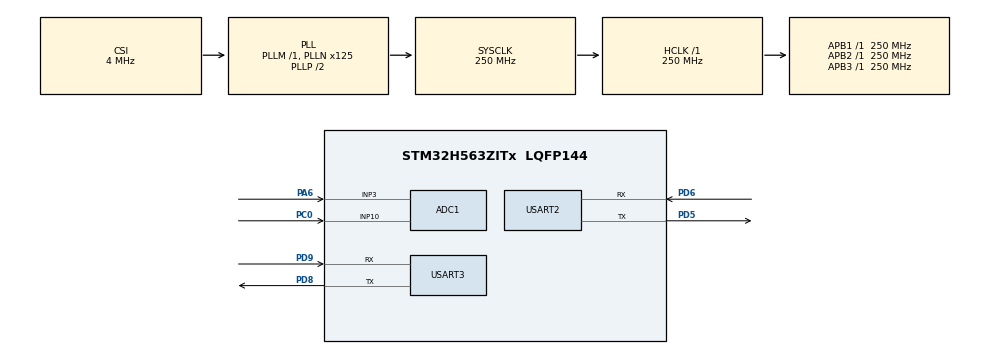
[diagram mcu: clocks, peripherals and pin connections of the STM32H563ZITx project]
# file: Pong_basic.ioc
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ADC1.Channel-0\#ChannelRegularConversion=ADC_CHANNEL_3
ADC1.Channel-1\#ChannelRegularConversion=ADC_CHANNEL_10
ADC1.DMAContinuousRequests=DISABLE
ADC1.EOCSelection=ADC_EOC_SINGLE_CONV
ADC1.MonitoredBy-0\#ChannelRegularConversion=__NULL
ADC1.MonitoredBy-1\#ChannelRegularConversion=__NULL
ADC1.NbrOfConversion=2
ADC1.NbrOfConversionFlag=1
ADC1.OffsetNumber-0\#ChannelRegularConversion=ADC_OFFSET_NONE
ADC1.OffsetNumber-1\#ChannelRegularConversion=ADC_OFFSET_NONE
ADC1.Rank-0\#ChannelRegularConversion=1
ADC1.Rank-1\#ChannelRegularConversion=2
ADC1.SamplingTime-0\#ChannelRegularConversion=ADC_SAMPLETIME_2CYCLES_5
ADC1.SamplingTime-1\#ChannelRegularConversion=ADC_SAMPLETIME_2CYCLES_5
ADC1.master=1
BOOTPATH.BootPathName=LEGACY
BOOTPATH.UserSelectedBootPath=LEGACY
CORTEX_M33_NS.userName=CORTEX_M33
Mcu.Family=STM32H5
Mcu.Name=STM32H563ZITx
Mcu.Package=LQFP144
NVIC.PriorityGroup=NVIC_PRIORITYGROUP_4
NVIC.USART3_IRQn=true\:0\:0\:false\:false\:true\:true\:true\:true
PA6.Signal=ADCx_INP3
PC0.Signal=ADCx_INP10
PD5.Mode=Asynchronous
PD5.Signal=USART2_TX
PD6.Mode=Asynchronous
PD6.Signal=USART2_RX
PD8.Mode=Asynchronous
PD8.Signal=USART3_TX
PD9.Mode=Asynchronous
PD9.Signal=USART3_RX
ProjectManager.HeapSize=0x200
ProjectManager.StackSize=0x400
ProjectManager.TargetToolchain=STM32CubeIDE
RCC.ADCFreq_Value=250000000
RCC.AHBFreq_Value=250000000
RCC.APB1Freq_Value=250000000
RCC.APB1TimFreq_Value=250000000
RCC.APB2Freq_Value=250000000
RCC.APB2TimFreq_Value=250000000
RCC.APB3Freq_Value=250000000
RCC.CSI_VALUE=4000000
RCC.CortexFreq_Value=250000000
RCC.EPOD_VALUE=4000000
RCC.HCLKFreq_Value=250000000
RCC.HSE_VALUE=25000000
RCC.HSI48_VALUE=48000000
RCC.HSI_VALUE=64000000
RCC.LSE_VALUE=32768
RCC.LSIRC_VALUE=32000
RCC.PLL2FRACN=0
RCC.PLL3FRACN=0
RCC.PLLFRACN=0
RCC.PLLN=125
RCC.SYSCLKFreq_VALUE=250000000
RCC.SYSCLKSource=RCC_SYSCLKSOURCE_PLLCLK
RCC.USBFreq_Value=48000000
RCC.VCOOutputFreq_Value=500000000
SH.ADCx_INP10.0=ADC1_INP10,IN10-Single-Ended
SH.ADCx_INP3.0=ADC1_INP3,IN3-Single-Ended
USART2.VirtualMode-Asynchronous=VM_ASYNC
USART3.VirtualMode-Asynchronous=VM_ASYNC
VP_BOOTPATH_VS_BOOTPATH.Mode=BP_Activate
VP_CORTEX_M33_NS_VS_Hclk.Mode=Hclk_Mode
VP_ICACHE_VS_ENABLE_ICACHE_MEMORY.Mode=Memoryregions
VP_MEMORYMAP_VS_MEMORYMAP.Mode=CurAppReg
VP_PWR_VS_LPOM.Mode=PowerOptimisation
VP_PWR_VS_SECSignals.Mode=Security/Privilege
board=custom

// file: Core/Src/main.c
/* USER CODE BEGIN Header */
/**
  ******************************************************************************
  * @file           : main.c
  * @brief          : Main program body
  ******************************************************************************
  * @attention
  *
  * Copyright (c) 2025 STMicroelectronics.
  * All rights reserved.
  *
  * This software is licensed under terms that can be found in the LICENSE file
  * in the root directory of this software component.
  * If no LICENSE file comes with this software, it is provided AS-IS.
  *
  ******************************************************************************
  */
/* USER CODE END Header */
#include "main.h"
#include "adc.h"
#include "icache.h"
#include "usart.h"
#include "gpio.h"

/* USER CODE BEGIN Includes */
#include "pong_game.h"

//#include <stdlib.h> // rand()
//#include "nextion.h"
//#include "game_settings.h"
/* USER CODE END Includes */

void SystemClock_Config(void);

int main(void)
{

  /* MCU Configuration--------------------------------------------------------*/

  /* Reset of all peripherals, Initializes the Flash interface and the Systick. */
  HAL_Init();

  /* Configure the system clock */
  SystemClock_Config();

  /* Initialize all configured peripherals */
  MX_GPIO_Init();
  MX_ICACHE_Init();
  MX_USART3_UART_Init();
  MX_ADC1_Init();
  MX_USART2_UART_Init();
  /* USER CODE BEGIN 2 */

  init_game();

  /* USER CODE END 2 */

  /* Infinite loop */
  /* USER CODE BEGIN WHILE */
  while (1)
  {
	run_game();
    /* USER CODE END WHILE */

  }
}

void SystemClock_Config(void)
{
  RCC_OscInitTypeDef RCC_OscInitStruct = {0};
  RCC_ClkInitTypeDef RCC_ClkInitStruct = {0};

  /** Configure the main internal regulator output voltage
  */
  __HAL_PWR_VOLTAGESCALING_CONFIG(PWR_REGULATOR_VOLTAGE_SCALE0);

  while(!__HAL_PWR_GET_FLAG(PWR_FLAG_VOSRDY)) {}

  /** Initializes the RCC Oscillators according to the specified parameters
  * in the RCC_OscInitTypeDef structure.
  */
  RCC_OscInitStruct.OscillatorType = RCC_OSCILLATORTYPE_CSI;
  RCC_OscInitStruct.CSIState = RCC_CSI_ON;
  RCC_OscInitStruct.CSICalibrationValue = RCC_CSICALIBRATION_DEFAULT;
  RCC_OscInitStruct.PLL.PLLState = RCC_PLL_ON;
  RCC_OscInitStruct.PLL.PLLSource = RCC_PLL1_SOURCE_CSI;
  RCC_OscInitStruct.PLL.PLLM = 1;
  RCC_OscInitStruct.PLL.PLLN = 125;
  RCC_OscInitStruct.PLL.PLLP = 2;
  RCC_OscInitStruct.PLL.PLLQ = 2;
  RCC_OscInitStruct.PLL.PLLR = 2;
  RCC_OscInitStruct.PLL.PLLRGE = RCC_PLL1_VCIRANGE_2;
  RCC_OscInitStruct.PLL.PLLVCOSEL = RCC_PLL1_VCORANGE_WIDE;
  RCC_OscInitStruct.PLL.PLLFRACN = 0;
  if (HAL_RCC_OscConfig(&RCC_OscInitStruct) != HAL_OK)
  {
    Error_Handler();
  }

  /** Initializes the CPU, AHB and APB buses clocks
  */
  RCC_ClkInitStruct.ClockType = RCC_CLOCKTYPE_HCLK|RCC_CLOCKTYPE_SYSCLK
                              |RCC_CLOCKTYPE_PCLK1|RCC_CLOCKTYPE_PCLK2
                              |RCC_CLOCKTYPE_PCLK3;
  RCC_ClkInitStruct.SYSCLKSource = RCC_SYSCLKSOURCE_PLLCLK;
  RCC_ClkInitStruct.AHBCLKDivider = RCC_SYSCLK_DIV1;
  RCC_ClkInitStruct.APB1CLKDivider = RCC_HCLK_DIV1;
  RCC_ClkInitStruct.APB2CLKDivider = RCC_HCLK_DIV1;
  RCC_ClkInitStruct.APB3CLKDivider = RCC_HCLK_DIV1;

  if (HAL_RCC_ClockConfig(&RCC_ClkInitStruct, FLASH_LATENCY_5) != HAL_OK)
  {
    Error_Handler();
  }

  /** Configure the programming delay
  */
  __HAL_FLASH_SET_PROGRAM_DELAY(FLASH_PROGRAMMING_DELAY_2);
}

void Error_Handler(void)
{
  __disable_irq();
  while (1)
  {
  }
}
